# H5 register map
Vendor: Allwinner; Series: H5; File version: 0.1
CPU: 0, little endian, MPU, no FPU, 0 interrupt priority bits
Registers are 32-bit, read-write, reset 0x0 unless marked. A register's access mark holds for its fields unless they carry their own. Offsets are from the block's base; [hi:lo] are bit positions; {n}, {i} and the like mark numbered series.

## CPU_CFG
Base 0x01700000
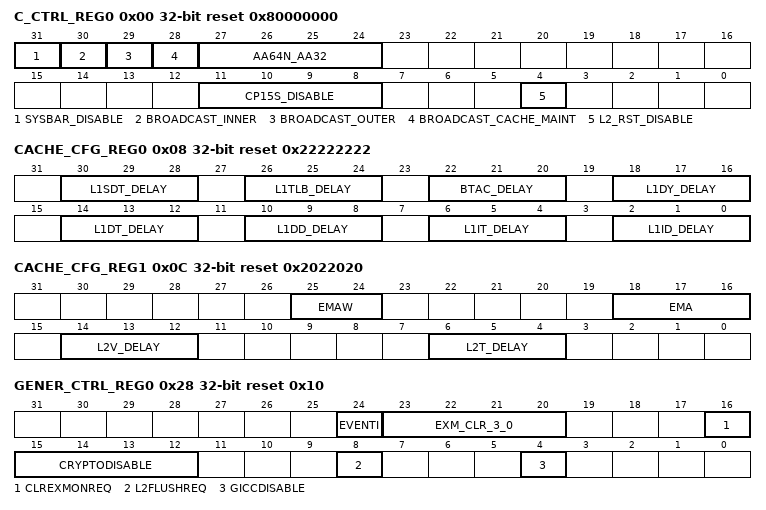
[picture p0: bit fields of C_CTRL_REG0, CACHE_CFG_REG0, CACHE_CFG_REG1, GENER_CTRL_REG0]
0x00 C_CTRL_REG0 reset 0x80000000 — Cluster Control Register0
  [31] SYSBAR_DISABLE — Disable broadcasting of barriers onto system bus 0: Barriers are broadcast onto system bus, this requires an AMBA4 interconnect. 1: Barriers are not broadcast onto the system bus. This is compatible with an AXI3 interconnect.
    0=Barriers are broadcast onto system bus, this requires an AMBA4 interconnect; 1=Barriers are not broadcast onto the system bus. This is compatible with an AXI3 interconnect.
  [30] BROADCAST_INNER — Enable broadcasting of Inner Shareable transactions 0: Inner shareable transactions are not broadcasted externally. 1: Inner shareable transactions are broadcasted externally.
    0=Inner shareable transactions are not broadcasted externally; 1=Inner shareable transactions are broadcasted externally
  [29] BROADCAST_OUTER — Enable broadcasting of outer shareable transactions 0: Outer Shareable transactions are not broadcasted externally. 1: Outer Shareable transactions are broadcasted externally.
    0=Outer Shareable transactions are not broadcasted externally; 1=Outer Shareable transactions are broadcasted externally
  [28] BROADCAST_CACHE_MAINT — Enable broadcasting of cache maintenance operations to downstream caches 0: Cache maintenance operations are not broadcasted to downstream caches. 1: Cache maintenance operations are broadcasted to downstream caches.
    0=Cache maintenance operations are not broadcasted to downstream caches; 1=Cache maintenance operations are broadcasted to downstream caches
  [27:24] AA64N_AA32 — AA64nAA32 Register width state. Determines which execution state the processor boots into after a cold reset. 0: AArch32 1: AArch64
  [11:8] CP15S_DISABLE — Disable write access to some secure CP15 register.
  [4] L2_RST_DISABLE — Disable automatic L2 cache invalidate at reset 0: L2 cache is reset by hardware. 1: L2 cache is not reset by hardware.
    0=reset (L2 cache is reset by hardware.); 1=not_reset (L2 cache is not reset by hardware.)
0x04 C_CTRL_REG1 — Cluster Control Register1
  [0] ACINACTM — Snoop interface is inactive and no longer accepting requests. 0: Snoop interface is active 1: Snoop interface is inactive
    0=active (Snoop interface is active); 1=inactive (Snoop interface is inactive)
0x08 CACHE_CFG_REG0 reset 0x22222222 — Cache parameters configuration register0
  [30:28] L1SDT_DELAY, [26:24] L1TLB_DELAY, [22:20] BTAC_DELAY, [18:16] L1DY_DELAY, [14:12] L1DT_DELAY, [10:8] L1DD_DELAY, [6:4] L1IT_DELAY, [2:0] L1ID_DELAY
0x0C CACHE_CFG_REG1 reset 0x2022020 — Cache parameters configuration register1
  [25:24] EMAW, [18:16] EMA, [14:12] L2V_DELAY, [6:4] L2T_DELAY
0x28 GENER_CTRL_REG0 reset 0x10 — General Control Register0
  [24] EVENTI — Event input for processor wake-up from WFE state.This bit must remain HIGH for at least one clock cycle to be visible by the cores.
  [23:20] EXM_CLR_3_0
  [16] CLREXMONREQ — Clearing of the external global exclusive monitor request.When this bit is asserted, it acts as a WFE wake-up event to all the cores in the MPCore device.
  [15:12] CRYPTODISABLE — Disable the Cryptography Extensions.
  [8] L2FLUSHREQ — L2 hardware flush request.
  [4] GICCDISABLE — Globally disables the CPU interface logic and routes the "External" signals directly to the processor: 0: Enable the GIC CPU interface logic. 1: Disable the GIC CPU interface logic.
    0=Enable the GIC CPU interface logic; 1=Disable the GIC CPU interface logic
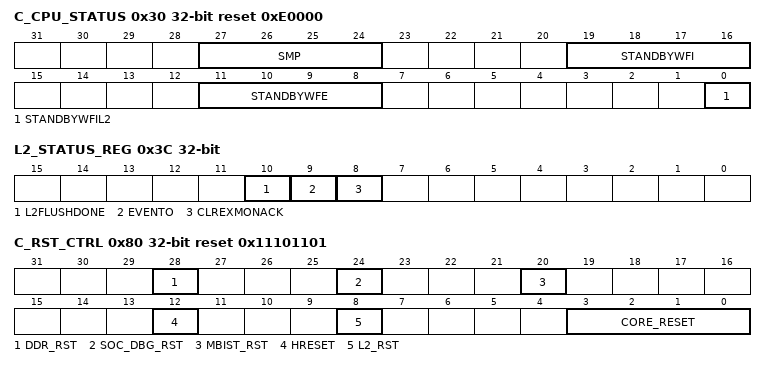
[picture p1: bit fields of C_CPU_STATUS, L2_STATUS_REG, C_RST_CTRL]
0x30 C_CPU_STATUS reset 0xE0000 — Cluster CPU Status Register
  [27:24] SMP ro — Indicates whether a core is taking part in coherency. 0: Disable 1: Enable
  [19:16] STANDBYWFI ro — Indicates if a core is in WFI standby mode: 0: Processor not in WFI standby mode. 1: Processor in WFI standby mode
  [11:8] STANDBYWFE ro — Indicates if a core is in the WFE standby mode: 0: Processor not in WFE standby mode 1: Processor in WFE standby mode
  [0] STANDBYWFIL2 ro — Indicates if the Cluster L2 memory system is in WFI standby mode. 0: Active 1: Idle
    0=Active; 1=Idle
0x3C L2_STATUS_REG
  [10] L2FLUSHDONE ro — L2 hardware flush complete
  [9] EVENTO ro — Event output. This bit is asserted HIGH for 3 clock cycles when any core in the cluster executes an SEV instruction.
  [8] CLREXMONACK ro — Clearing of the external global exclusive monitor acknowledge.
0x80 C_RST_CTRL reset 0x11101101 — Cluster Reset Control Register
  [28] DDR_RST — AXI2MBUS Logic Circuit Reset. 0: Assert 1: De-assert
    0=Assert; 1=deassert
  [24] SOC_DBG_RST — Cluster SOC Debug P_Reset. Clear this bit will reset the SOC Debug Bus Logic and it will automatically change to 1 after 64 p_cycles. 0: Assert 1: De-assert.
    0=Assert; 1=deassert
  [20] MBIST_RST — CPUBIST Reset. The reset signal for test. 0: Assert 1: De-assert
    0=Assert; 1=deassert
  [12] HRESET — Cluster H_Reset. Reset all the Cluster Logic and Cluster Interface Logic. 0: Assert 1: De-assert
    0=Assert; 1=deassert
  [8] L2_RST — Cluster L2 Cache Reset 0: Assert 1: De-assert
    0=Assert; 1=deassert
  [3:0] CORE_RESET — Control a Core Reset Assert. 0: Assert 1: De-assert
{0xA0+8i} RVBARADDR{i}_L (i=0..3) — Reset Vector Base Address Register{i}_L
  [31:2] RVBARDDR_31_2 — RVBARDDR[31:2] Reset Vector Base Address[39:2] for executing in 64-bit state (AArch64)of CPU{i}.
0xA4 RVBARADDR0_H — Reset Vector Base Address Register0_H
  [7:0] RVBARDDR_39_32 — RVBARDDR[39:32] Reset Vector Base Address[39:2]for executing in 64-bit state (AArch64) of CPU0.
{0xA4+8i} RVBARADDR{i}_H (i=1..3) — Reset Vector Base Address Register{i}_H
  [7:0] RVBARDDR_39_32 — RVBARDDR[39:32] Reset Vector Base Address[39:2] for executing in 64-bit state (AArch64) of CPU{i}.
